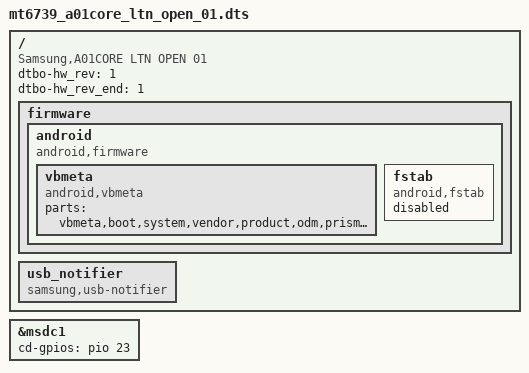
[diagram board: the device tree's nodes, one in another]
/* Generated by MediaTek
 * If these files should be chaned, then please make a sync with MTK
*/

/dts-v1/;
/plugin/;

#include "../k39tv1_bsp_1g_titan-02.dts"
#include "cust_a01core_cis_ser-gpio02.dtsi"
#include "mt6739_a01core_camera_01.dtsi"
#include "battery-data-a01-core-common.dtsi"
#include "mt6739_a01core_eif_common.dtsi"
#include "mt6739_a3core_audio_common.dtsi"
#include "mt6739_a3core_sensor_r01.dtsi"
#include "mt6739_a01core_input_common.dtsi"
#include "mt6739_a01_pm_common.dtsi"
#include "display_lcd_a01core_common.dtsi"
#include "mt6739_a01core_abc_common.dtsi"

/* Add Samsung configuration over here */
/ {
	compatible = "Samsung,A01CORE LTN OPEN 01", "Mediatek,MT6739";
	dtbo-hw_rev = <1>;
	dtbo-hw_rev_end = <1>;

	fragment@model {
		target-path = "/";
		__overlay__ {
			firmware {
				android {
					compatible = "android,firmware";
					vbmeta {
						compatible = "android,vbmeta";
						parts = "vbmeta,boot,system,vendor,product,odm,prism,optics,recovery";
					};
					fstab {
						compatible = "android,fstab";
						status = "disabled";
					};
				};
			};
			usb_notifier {
				compatible = "samsung,usb-notifier";
			};
		};
	};
};

&msdc1 {
       cd-gpios = <&pio 23 0>;
};
/*End of this file, DO NOT ADD ANYTHING HERE*/
